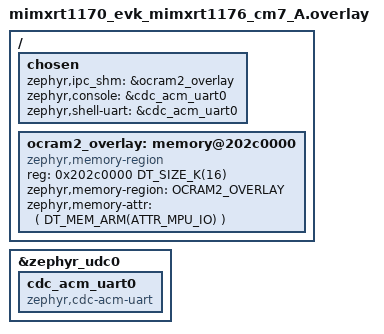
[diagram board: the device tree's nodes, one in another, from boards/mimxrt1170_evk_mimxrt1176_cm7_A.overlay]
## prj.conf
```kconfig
CONFIG_PRINTK=y
CONFIG_IPM=y
CONFIG_TIMESLICE_SIZE=1
CONFIG_MAIN_STACK_SIZE=2048
CONFIG_HEAP_MEM_POOL_SIZE=4096
CONFIG_OPENAMP=y
CONFIG_OPENAMP_SLAVE=n



#From usb/console
CONFIG_USB_DEVICE_STACK=y
CONFIG_USB_DEVICE_PRODUCT="Zephyr USB console sample"
CONFIG_USB_DEVICE_PID=0x0004
CONFIG_USB_DEVICE_INITIALIZE_AT_BOOT=n

CONFIG_SERIAL=y
CONFIG_CONSOLE=y
CONFIG_UART_CONSOLE=y
CONFIG_UART_LINE_CTRL=y



#From net/syslog_net
CONFIG_NETWORKING=y
CONFIG_NET_UDP=y
CONFIG_ENTROPY_GENERATOR=y
CONFIG_TEST_RANDOM_GENERATOR=y
CONFIG_INIT_STACKS=y
CONFIG_NET_PKT_RX_COUNT=32
CONFIG_NET_PKT_TX_COUNT=32
CONFIG_NET_BUF_RX_COUNT=32
CONFIG_NET_BUF_TX_COUNT=32
CONFIG_NET_SOCKETS=y

CONFIG_NET_IF_UNICAST_IPV6_ADDR_COUNT=3
CONFIG_NET_IF_MCAST_IPV6_ADDR_COUNT=5

CONFIG_NET_LOG=y
CONFIG_LOG=y

# Deferred mode is required, synchronous mode does not work with network syslog
# as it would cause the sent packet to be malformed (contains only 1 byte data)
CONFIG_LOG_MODE_DEFERRED=y

CONFIG_NET_IPV6=y
CONFIG_NET_IPV4=y
CONFIG_NET_DHCPV4=n

CONFIG_NET_SHELL=y

CONFIG_NET_CONFIG_SETTINGS=y
CONFIG_NET_CONFIG_NEED_IPV6=n
CONFIG_NET_CONFIG_NEED_IPV4=y

CONFIG_NET_CONFIG_MY_IPV4_ADDR="192.168.1.100"
CONFIG_NET_CONFIG_PEER_IPV4_ADDR="192.168.1.5"

# logging net backend config
CONFIG_LOG_BACKEND_NET=y
CONFIG_LOG_BACKEND_NET_SERVER="192.168.1.5:514"

# Get a proper libc by default in order to get working time function support
CONFIG_REQUIRES_FULL_LIBC=y
```

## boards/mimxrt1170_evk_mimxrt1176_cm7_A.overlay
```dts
/*
 * Copyright (c) 2022 NXP
 *
 * SPDX-License-Identifier: Apache-2.0
 */

#include <zephyr/dt-bindings/memory-attr/memory-attr-arm.h>

/ {
	chosen {
		zephyr,ipc_shm = &ocram2_overlay;
	};

	/* OpenAMP fails with full 512K OCRAM2 memory region as shared memory.
	 * Define a subset of the OCRAM2 region for demo to use
	 * Note that shared memory must have specific MPU attributes set.
	 */
	ocram2_overlay: memory@202c0000{
		compatible = "zephyr,memory-region", "mmio-sram";
		reg = <0x202c0000 DT_SIZE_K(16)>;
		zephyr,memory-region="OCRAM2_OVERLAY";
		zephyr,memory-attr = <( DT_MEM_ARM(ATTR_MPU_IO) )>;
	};
};


/* From usb/console/app.overlay */
/ {
	chosen {
		zephyr,console = &cdc_acm_uart0;
		zephyr,shell-uart = &cdc_acm_uart0;
	};
};

&zephyr_udc0 {
	cdc_acm_uart0: cdc_acm_uart0 {
		compatible = "zephyr,cdc-acm-uart";
	};
};
```

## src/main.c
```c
/*
 * Copyright (c) 2018, NXP
 * Copyright (c) 2018, Nordic Semiconductor ASA
 * Copyright (c) 2018-2019, Linaro Limited
 *
 * SPDX-License-Identifier: Apache-2.0
 */

#include <zephyr/kernel.h>
#include <zephyr/drivers/ipm.h>
#include <zephyr/sys/printk.h>
#include <zephyr/device.h>
#include <stdio.h>
#include <stdlib.h>
#include <string.h>
#include <zephyr/init.h>

#include "common.h"

#include <zephyr/kernel.h>
#include <zephyr/sys/printk.h>

#include <zephyr/drivers/uart.h>

#include <zephyr/logging/log.h>
LOG_MODULE_REGISTER(net_syslog, LOG_LEVEL_DBG);
#include <zephyr/logging/log_backend.h>
#include <zephyr/logging/log_backend_net.h>
#include <zephyr/logging/log_ctrl.h>

#include <zephyr/sys/printk.h>
#include <zephyr/usb/usb_device.h>
#include <zephyr/usb/usbd.h>
#include <zephyr/drivers/uart.h>

int main(void)
{
	if (usb_enable(NULL)) {
		
	}
	int i = 0;
	while (1) {
		printk("OpenAMP demo ended.\n");
		printf("OpenAMP demo ended.\n");
		LOG_ERR("Info message (%d)", i++);
		k_sleep(K_MSEC(1000));
	}
}
```
